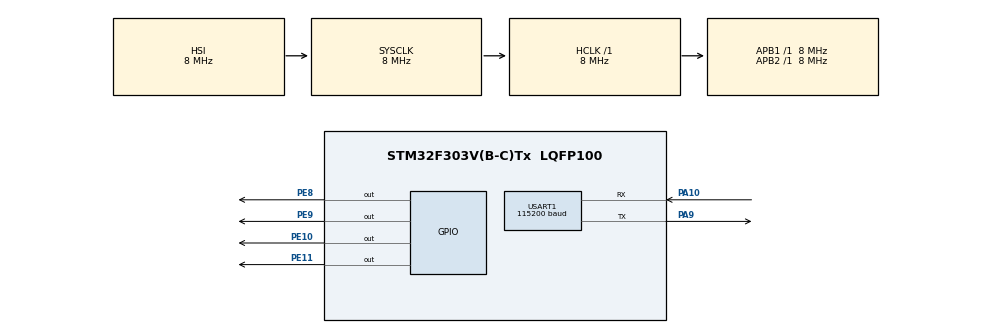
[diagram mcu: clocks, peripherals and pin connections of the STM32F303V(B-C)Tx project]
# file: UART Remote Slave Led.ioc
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Mcu.Family=STM32F3
Mcu.Name=STM32F303V(B-C)Tx
Mcu.Package=LQFP100
NVIC.PriorityGroup=NVIC_PRIORITYGROUP_4
PA10.Mode=Asynchronous
PA10.Signal=USART1_RX
PA9.Mode=Asynchronous
PA9.Signal=USART1_TX
PE10.Signal=GPIO_Output
PE11.Signal=GPIO_Output
PE8.Signal=GPIO_Output
PE9.Signal=GPIO_Output
ProjectManager.HeapSize=0x200
ProjectManager.StackSize=0x400
ProjectManager.TargetToolchain=MDK-ARM V5.27
RCC.AHBFreq_Value=8000000
RCC.APB1Freq_Value=8000000
RCC.APB2Freq_Value=8000000
RCC.CortexFreq_Value=8000000
RCC.HSE_VALUE=8000000
RCC.HSI_VALUE=8000000
RCC.LSE_VALUE=32768
RCC.SYSCLKFreq_VALUE=8000000
USART1.BaudRate=115200
USART1.VirtualMode-Asynchronous=VM_ASYNC
board=custom

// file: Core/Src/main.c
/* USER CODE BEGIN Header */
/**
  ******************************************************************************
  * @file           : main.c
  * @brief          : Main program body
  ******************************************************************************
  * @attention
  *
  * <h2><center>&copy; Copyright (c) 2023 STMicroelectronics.
  * All rights reserved.</center></h2>
  *
  * This software component is licensed by ST under BSD 3-Clause license,
  * the "License"; You may not use this file except in compliance with the
  * License. You may obtain a copy of the License at:
  *                        opensource.org/licenses/BSD-3-Clause
  *
  ******************************************************************************
  */
/* USER CODE END Header */
#include "main.h"

UART_HandleTypeDef huart1;

/* USER CODE BEGIN PV */
	uint8_t Number=0;
	const uint16_t base = 0x0100;
/* USER CODE END PV */

void SystemClock_Config(void);
static void MX_GPIO_Init(void);
static void MX_USART1_UART_Init(void);

int main(void)
{

  /* MCU Configuration--------------------------------------------------------*/

  /* Reset of all peripherals, Initializes the Flash interface and the Systick. */
  HAL_Init();

  /* Configure the system clock */
  SystemClock_Config();

  /* Initialize all configured peripherals */
  MX_GPIO_Init();
  MX_USART1_UART_Init();

  /* Infinite loop */
  /* USER CODE BEGIN WHILE */
  while (1)
  {

		HAL_UART_Receive(&huart1, &Number ,sizeof(Number), HAL_MAX_DELAY);

		HAL_GPIO_WritePin(GPIOE,Number*base,GPIO_PIN_SET);
		HAL_Delay(2000);
		HAL_GPIO_WritePin(GPIOE,Number*base,GPIO_PIN_RESET);

    /* USER CODE END WHILE */

  }
}

void SystemClock_Config(void)
{
  RCC_OscInitTypeDef RCC_OscInitStruct = {0};
  RCC_ClkInitTypeDef RCC_ClkInitStruct = {0};
  RCC_PeriphCLKInitTypeDef PeriphClkInit = {0};

  /** Initializes the RCC Oscillators according to the specified parameters
  * in the RCC_OscInitTypeDef structure.
  */
  RCC_OscInitStruct.OscillatorType = RCC_OSCILLATORTYPE_HSI;
  RCC_OscInitStruct.HSIState = RCC_HSI_ON;
  RCC_OscInitStruct.HSICalibrationValue = RCC_HSICALIBRATION_DEFAULT;
  RCC_OscInitStruct.PLL.PLLState = RCC_PLL_NONE;
  if (HAL_RCC_OscConfig(&RCC_OscInitStruct) != HAL_OK)
  {
    Error_Handler();
  }
  /** Initializes the CPU, AHB and APB buses clocks
  */
  RCC_ClkInitStruct.ClockType = RCC_CLOCKTYPE_HCLK|RCC_CLOCKTYPE_SYSCLK
                              |RCC_CLOCKTYPE_PCLK1|RCC_CLOCKTYPE_PCLK2;
  RCC_ClkInitStruct.SYSCLKSource = RCC_SYSCLKSOURCE_HSI;
  RCC_ClkInitStruct.AHBCLKDivider = RCC_SYSCLK_DIV1;
  RCC_ClkInitStruct.APB1CLKDivider = RCC_HCLK_DIV1;
  RCC_ClkInitStruct.APB2CLKDivider = RCC_HCLK_DIV1;

  if (HAL_RCC_ClockConfig(&RCC_ClkInitStruct, FLASH_LATENCY_0) != HAL_OK)
  {
    Error_Handler();
  }
  PeriphClkInit.PeriphClockSelection = RCC_PERIPHCLK_USART1;
  PeriphClkInit.Usart1ClockSelection = RCC_USART1CLKSOURCE_PCLK2;
  if (HAL_RCCEx_PeriphCLKConfig(&PeriphClkInit) != HAL_OK)
  {
    Error_Handler();
  }
}

static void MX_USART1_UART_Init(void)
{

  huart1.Instance = USART1;
  huart1.Init.BaudRate = 115200;
  huart1.Init.WordLength = UART_WORDLENGTH_8B;
  huart1.Init.StopBits = UART_STOPBITS_1;
  huart1.Init.Parity = UART_PARITY_NONE;
  huart1.Init.Mode = UART_MODE_TX_RX;
  huart1.Init.HwFlowCtl = UART_HWCONTROL_NONE;
  huart1.Init.OverSampling = UART_OVERSAMPLING_16;
  huart1.Init.OneBitSampling = UART_ONE_BIT_SAMPLE_DISABLE;
  huart1.AdvancedInit.AdvFeatureInit = UART_ADVFEATURE_NO_INIT;
  if (HAL_UART_Init(&huart1) != HAL_OK)
  {
    Error_Handler();
  }

}

static void MX_GPIO_Init(void)
{
  GPIO_InitTypeDef GPIO_InitStruct = {0};

  /* GPIO Ports Clock Enable */
  __HAL_RCC_GPIOE_CLK_ENABLE();
  __HAL_RCC_GPIOA_CLK_ENABLE();

  /*Configure GPIO pin Output Level */
  HAL_GPIO_WritePin(GPIOE, GPIO_PIN_8|GPIO_PIN_9|GPIO_PIN_10|GPIO_PIN_11, GPIO_PIN_RESET);

  /*Configure GPIO pins : PE8 PE9 PE10 PE11 */
  GPIO_InitStruct.Pin = GPIO_PIN_8|GPIO_PIN_9|GPIO_PIN_10|GPIO_PIN_11;
  GPIO_InitStruct.Mode = GPIO_MODE_OUTPUT_PP;
  GPIO_InitStruct.Pull = GPIO_NOPULL;
  GPIO_InitStruct.Speed = GPIO_SPEED_FREQ_LOW;
  HAL_GPIO_Init(GPIOE, &GPIO_InitStruct);

}

void Error_Handler(void)
{
  __disable_irq();
  while (1)
  {
  }
}

/************************ (C) COPYRIGHT STMicroelectronics *****END OF FILE****/
